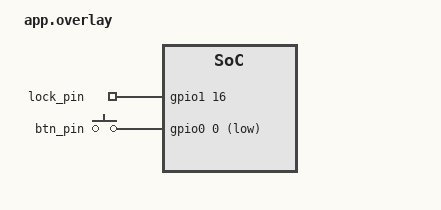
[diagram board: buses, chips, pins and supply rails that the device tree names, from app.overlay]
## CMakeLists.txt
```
# SPDX-License-Identifier: Apache-2.0

cmake_minimum_required(VERSION 3.20.0)

list(APPEND EXTRA_DTC_OVERLAY_FILE ${CMAKE_CURRENT_SOURCE_DIR}/app.overlay)

find_package(Zephyr REQUIRED HINTS $ENV{ZEPHYR_BASE})
project(elock)

target_sources(app PRIVATE
    src/main.c
    src/lock_ctrl.c
    src/button.c
    src/wifi_manager.c
    src/http_server.c
)

target_include_directories(app PRIVATE src)

zephyr_linker_sources(SECTIONS sections-rom.ld)

generate_inc_file_for_target(app
    src/web/index.html
    ${ZEPHYR_BINARY_DIR}/include/generated/index_html.inc)
```

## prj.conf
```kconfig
# --- WiFi (ESP32 driver) ---
CONFIG_WIFI=y
CONFIG_WIFI_NM=y
CONFIG_WIFI_ESP32=y
CONFIG_WIFI_USAGE_MODE_STA_AP=y

# --- Networking ---
CONFIG_NETWORKING=y
CONFIG_NET_CONFIG_AUTO_INIT=n
CONFIG_NET_CONNECTION_MANAGER=y
CONFIG_NET_IPV4=y
CONFIG_NET_TCP=y
CONFIG_NET_UDP=y
CONFIG_NET_SOCKETS=y
CONFIG_NET_DHCPV4=y
CONFIG_NET_DHCPV4_SERVER=y
CONFIG_NET_L2_ETHERNET=y
CONFIG_NET_L2_WIFI_MGMT=y
CONFIG_NET_MGMT=y
CONFIG_NET_MGMT_EVENT=y
CONFIG_NET_MGMT_EVENT_INFO=y
CONFIG_NET_MGMT_EVENT_QUEUE_SIZE=10
CONFIG_NET_MGMT_EVENT_STACK_SIZE=4096
CONFIG_NET_IF_MAX_IPV4_COUNT=2
CONFIG_NET_IF_MAX_IPV6_COUNT=2
CONFIG_NET_PKT_RX_COUNT=16
CONFIG_NET_PKT_TX_COUNT=16

# --- POSIX needed by HTTP server (eventfd, etc.) ---
CONFIG_POSIX_API=y
CONFIG_EVENTFD=y
CONFIG_ZVFS_EVENTFD_MAX=8
CONFIG_ZVFS_POLL_MAX=16

# --- HTTP server (HTTP/1.1 only, no TLS) ---
CONFIG_HTTP_PARSER=y
CONFIG_HTTP_PARSER_URL=y
CONFIG_HTTP_SERVER=y
CONFIG_HTTP_SERVER_MAX_CLIENTS=3
CONFIG_HTTP_SERVER_MAX_URL_LENGTH=128

# --- Settings on NVS for WiFi credential persistence ---
CONFIG_FLASH=y
CONFIG_FLASH_MAP=y
CONFIG_NVS=y
CONFIG_SETTINGS=y
CONFIG_SETTINGS_NVS=y

# --- GPIO + logging ---
CONFIG_GPIO=y
CONFIG_LOG=y
CONFIG_NET_LOG=y

# --- Stacks ---
CONFIG_MAIN_STACK_SIZE=4096
CONFIG_SYSTEM_WORKQUEUE_STACK_SIZE=2048

# --- Reboot ---
CONFIG_REBOOT=y
```

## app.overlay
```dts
/ {
    wifi_ap: wifi_ap {
        compatible = "espressif,esp32-wifi";
        status = "okay";
    };

    aliases {
        lock-out = &lock_gpio_node;
        btn-lock = &btn_gpio_node;
    };

    lock_gpio_node: lock-output {
        compatible = "gpio-leds";
        lock_pin: lock_pin {
            gpios = <&gpio1 16 GPIO_ACTIVE_HIGH>;
        };
    };

    btn_gpio_node: lock-button {
        compatible = "gpio-keys";
        btn_pin: btn_pin {
            gpios = <&gpio0 0 (GPIO_ACTIVE_LOW | GPIO_PULL_UP)>;
        };
    };
};
```

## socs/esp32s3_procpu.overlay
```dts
/ {
    chosen {
        zephyr,console = &usb_serial;
        zephyr,shell-uart = &usb_serial;
    };
};
&usb_serial {
    status = "okay";
};
```

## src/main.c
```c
#include <zephyr/kernel.h>
#include <zephyr/logging/log.h>

#include "button.h"
#include "http_server.h"
#include "lock_ctrl.h"
#include "wifi_manager.h"

LOG_MODULE_REGISTER(main, LOG_LEVEL_INF);

int main(void)
{
	LOG_INF("SmartLock boot");

	if (lock_ctrl_init() < 0) {
		LOG_ERR("lock_ctrl_init failed");
	}
	if (button_init() < 0) {
		LOG_ERR("button_init failed");
	}
	if (wifi_manager_init() < 0) {
		LOG_ERR("wifi_manager_init failed");
	}
	if (http_server_thread_init() < 0) {
		LOG_ERR("http_server_thread_init failed");
	}

	return 0;
}
```

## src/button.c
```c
#include <zephyr/kernel.h>
#include <zephyr/drivers/gpio.h>
#include <zephyr/logging/log.h>

#include "button.h"
#include "lock_ctrl.h"

LOG_MODULE_REGISTER(button, LOG_LEVEL_INF);

#define BTN_NODE DT_CHILD(DT_ALIAS(btn_lock), btn_pin)
BUILD_ASSERT(DT_NODE_EXISTS(BTN_NODE), "btn-lock alias / btn_pin child missing");

static const struct gpio_dt_spec btn_gpio = GPIO_DT_SPEC_GET(BTN_NODE, gpios);

#define BUTTON_THREAD_STACK_SIZE 1024
#define BUTTON_THREAD_PRIORITY   3
#define BUTTON_POLL_MS           10
#define BUTTON_DEBOUNCE_MS       50

static K_THREAD_STACK_DEFINE(button_thread_stack, BUTTON_THREAD_STACK_SIZE);
static struct k_thread button_thread_data;

static void button_thread_entry(void *p1, void *p2, void *p3)
{
	ARG_UNUSED(p1);
	ARG_UNUSED(p2);
	ARG_UNUSED(p3);

	bool last_stable = false;
	bool candidate = false;
	int64_t candidate_since = 0;

	while (1) {
		int raw = gpio_pin_get_dt(&btn_gpio);

		if (raw < 0) {
			k_msleep(BUTTON_POLL_MS);
			continue;
		}

		bool pressed = raw != 0;

		if (pressed != candidate) {
			candidate = pressed;
			candidate_since = k_uptime_get();
		} else if (candidate != last_stable &&
			   (k_uptime_get() - candidate_since) >= BUTTON_DEBOUNCE_MS) {
			last_stable = candidate;
			if (last_stable) {
				LOG_INF("Button pressed -> lock");
				lock_ctrl_lock();
			}
		}

		k_msleep(BUTTON_POLL_MS);
	}
}

int button_init(void)
{
	int ret;

	if (!gpio_is_ready_dt(&btn_gpio)) {
		LOG_ERR("Button GPIO not ready");
		return -ENODEV;
	}

	ret = gpio_pin_configure_dt(&btn_gpio, GPIO_INPUT);
	if (ret < 0) {
		LOG_ERR("Configure button GPIO failed: %d", ret);
		return ret;
	}

	k_thread_create(&button_thread_data, button_thread_stack,
			K_THREAD_STACK_SIZEOF(button_thread_stack),
			button_thread_entry, NULL, NULL, NULL,
			BUTTON_THREAD_PRIORITY, 0, K_NO_WAIT);
	k_thread_name_set(&button_thread_data, "button_thread");

	return 0;
}
```

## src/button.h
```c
#ifndef ELOCK_BUTTON_H_
#define ELOCK_BUTTON_H_

/*
 * Owns GPIO0 with internal pull-up. A dedicated polling thread
 * (button_thread) debounces 50ms in software and calls lock_ctrl_lock()
 * on press.
 */

int button_init(void);

#endif /* ELOCK_BUTTON_H_ */
```

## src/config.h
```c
#ifndef ELOCK_CONFIG_H_
#define ELOCK_CONFIG_H_

#define LOCK_PIN_CODE           "123456"
#define LOCK_UNLOCK_DURATION_S  5

#define WIFI_RETRY_COUNT        5
#define WIFI_RETRY_DELAY_MS     3000
#define WIFI_AP_SSID            "SmartLock-Setup"
#define WIFI_AP_CHANNEL         6
#define WIFI_AP_IP              "192.168.4.1"
#define WIFI_AP_NETMASK         "255.255.255.0"

#define HTTP_SERVER_PORT        80

#define SETTINGS_KEY_WIFI_SSID  "elock/wifi/ssid"
#define SETTINGS_KEY_WIFI_PSK   "elock/wifi/psk"

#define WIFI_SSID_MAX_LEN       32
#define WIFI_PSK_MAX_LEN        64

#endif /* ELOCK_CONFIG_H_ */
```

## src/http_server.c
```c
#include <string.h>
#include <stdio.h>

#include <zephyr/kernel.h>
#include <zephyr/logging/log.h>
#include <zephyr/net/http/server.h>
#include <zephyr/net/http/service.h>
#include <zephyr/net/http/status.h>

#include "config.h"
#include "http_server.h"
#include "lock_ctrl.h"
#include "wifi_manager.h"

LOG_MODULE_REGISTER(http_srv, LOG_LEVEL_INF);

#define HTTP_THREAD_STACK_SIZE 4096
#define HTTP_THREAD_PRIORITY   7

static K_THREAD_STACK_DEFINE(http_thread_stack, HTTP_THREAD_STACK_SIZE);
static struct k_thread http_thread_data;

#define POST_BUF_SIZE 256

static const uint8_t index_html[] = {
#include "index_html.inc"
};

static const char config_html[] =
	"<!doctype html><html><head><meta charset=\"utf-8\">"
	"<title>SmartLock Setup</title></head><body>"
	"<h1>WiFi Setup</h1>"
	"<form method=\"POST\" action=\"/config\">"
	"<p><label>SSID: <input name=\"ssid\" maxlength=\"32\" required></label></p>"
	"<p><label>Password: <input name=\"password\" type=\"password\" maxlength=\"64\"></label></p>"
	"<button type=\"submit\">Save & Reboot</button>"
	"</form></body></html>";

static const char unlock_ok_body[]   = "OK";
static const char unlock_bad_body[]  = "Invalid PIN";
static const char config_ok_body[]   = "Saved. Rebooting...";
static const char not_found_body[]   = "Not found";
static const char bad_request_body[] = "Bad request";

static int find_form_field(const char *body, size_t body_len,
			   const char *key, char *out, size_t out_size)
{
	size_t key_len = strlen(key);
	const char *p = body;
	const char *end = body + body_len;

	while (p < end) {
		const char *amp = memchr(p, '&', end - p);
		const char *seg_end = amp ? amp : end;

		if ((size_t)(seg_end - p) > key_len &&
		    p[key_len] == '=' &&
		    memcmp(p, key, key_len) == 0) {
			const char *vstart = p + key_len + 1;
			size_t vlen = seg_end - vstart;

			if (vlen >= out_size) {
				return -ENOMEM;
			}
			memcpy(out, vstart, vlen);
			out[vlen] = '\0';
			return (int)vlen;
		}

		if (!amp) {
			break;
		}
		p = amp + 1;
	}

	return -ENOENT;
}

static int collect_body(enum http_transaction_status status,
			const struct http_request_ctx *req,
			uint8_t *buf, size_t buf_size, size_t *cursor)
{
	if (status == HTTP_SERVER_TRANSACTION_ABORTED ||
	    status == HTTP_SERVER_TRANSACTION_COMPLETE) {
		*cursor = 0;
		return -EAGAIN;
	}

	if (req->data_len + *cursor > buf_size) {
		*cursor = 0;
		return -ENOMEM;
	}

	memcpy(buf + *cursor, req->data, req->data_len);
	*cursor += req->data_len;

	if (status == HTTP_SERVER_REQUEST_DATA_FINAL) {
		return 0;
	}
	return -EINPROGRESS;
}

static void set_text_response(struct http_response_ctx *resp,
			      enum http_status status,
			      const char *body, size_t body_len)
{
	static const struct http_header text_headers[] = {
		{.name = "Content-Type", .value = "text/plain"},
	};

	resp->status = status;
	resp->headers = text_headers;
	resp->header_count = ARRAY_SIZE(text_headers);
	resp->body = (const uint8_t *)body;
	resp->body_len = body_len;
	resp->final_chunk = true;
}

static int index_handler(struct http_client_ctx *client,
			 enum http_transaction_status status,
			 const struct http_request_ctx *request_ctx,
			 struct http_response_ctx *response_ctx,
			 void *user_data)
{
	ARG_UNUSED(client);
	ARG_UNUSED(request_ctx);
	ARG_UNUSED(user_data);

	if (status != HTTP_SERVER_REQUEST_DATA_FINAL) {
		return 0;
	}

	static const struct http_header html_headers[] = {
		{.name = "Content-Type", .value = "text/html"},
	};

	response_ctx->status = HTTP_200_OK;
	response_ctx->headers = html_headers;
	response_ctx->header_count = ARRAY_SIZE(html_headers);
	response_ctx->body = index_html;
	response_ctx->body_len = sizeof(index_html);
	response_ctx->final_chunk = true;
	return 0;
}

static int status_handler(struct http_client_ctx *client,
			  enum http_transaction_status status,
			  const struct http_request_ctx *request_ctx,
			  struct http_response_ctx *response_ctx,
			  void *user_data)
{
	ARG_UNUSED(client);
	ARG_UNUSED(request_ctx);
	ARG_UNUSED(user_data);

	if (status != HTTP_SERVER_REQUEST_DATA_FINAL) {
		return 0;
	}

	static char body[160];
	const char *ip = wifi_manager_get_ip();
	int n;

	if (ip[0]) {
		n = snprintf(body, sizeof(body),
			     "{\"locked\":%s,\"wifi\":\"%s\",\"ip\":\"%s\","
			     "\"temp\":null,\"humidity\":null}",
			     lock_ctrl_is_locked() ? "true" : "false",
			     wifi_manager_get_state(), ip);
	} else {
		n = snprintf(body, sizeof(body),
			     "{\"locked\":%s,\"wifi\":\"%s\",\"ip\":null,"
			     "\"temp\":null,\"humidity\":null}",
			     lock_ctrl_is_locked() ? "true" : "false",
			     wifi_manager_get_state());
	}

	if (n < 0 || n >= (int)sizeof(body)) {
		response_ctx->status = HTTP_500_INTERNAL_SERVER_ERROR;
		response_ctx->final_chunk = true;
		return 0;
	}

	static const struct http_header json_headers[] = {
		{.name = "Content-Type", .value = "application/json"},
		{.name = "Cache-Control", .value = "no-store"},
	};

	response_ctx->status = HTTP_200_OK;
	response_ctx->headers = json_headers;
	response_ctx->header_count = ARRAY_SIZE(json_headers);
	response_ctx->body = (const uint8_t *)body;
	response_ctx->body_len = n;
	response_ctx->final_chunk = true;
	return 0;
}

static struct http_resource_detail_dynamic status_detail = {
	.common = {
		.type = HTTP_RESOURCE_TYPE_DYNAMIC,
		.bitmask_of_supported_http_methods = BIT(HTTP_GET),
	},
	.cb = status_handler,
};

static struct http_resource_detail_dynamic index_detail = {
	.common = {
		.type = HTTP_RESOURCE_TYPE_DYNAMIC,
		.bitmask_of_supported_http_methods = BIT(HTTP_GET),
	},
	.cb = index_handler,
};

static int unlock_handler(struct http_client_ctx *client,
			  enum http_transaction_status status,
			  const struct http_request_ctx *request_ctx,
			  struct http_response_ctx *response_ctx,
			  void *user_data)
{
	ARG_UNUSED(client);
	ARG_UNUSED(user_data);

	static uint8_t buf[POST_BUF_SIZE];
	static size_t cursor;

	int rc = collect_body(status, request_ctx, buf, sizeof(buf), &cursor);

	if (rc == -EINPROGRESS) {
		return 0;
	}
	if (rc == -EAGAIN) {
		return 0;
	}
	if (rc == -ENOMEM) {
		set_text_response(response_ctx, HTTP_400_BAD_REQUEST,
				  bad_request_body, sizeof(bad_request_body) - 1);
		return 0;
	}

	char pin[16];
	int got = find_form_field((const char *)buf, cursor, "pin",
				  pin, sizeof(pin));
	cursor = 0;

	if (got < 0) {
		set_text_response(response_ctx, HTTP_400_BAD_REQUEST,
				  bad_request_body, sizeof(bad_request_body) - 1);
		return 0;
	}

	if (strcmp(pin, LOCK_PIN_CODE) == 0) {
		LOG_INF("PIN OK -> unlock");
		lock_ctrl_unlock();
		set_text_response(response_ctx, HTTP_200_OK,
				  unlock_ok_body, sizeof(unlock_ok_body) - 1);
	} else {
		LOG_WRN("PIN rejected");
		set_text_response(response_ctx, HTTP_403_FORBIDDEN,
				  unlock_bad_body, sizeof(unlock_bad_body) - 1);
	}
	return 0;
}

static struct http_resource_detail_dynamic unlock_detail = {
	.common = {
		.type = HTTP_RESOURCE_TYPE_DYNAMIC,
		.bitmask_of_supported_http_methods = BIT(HTTP_POST),
	},
	.cb = unlock_handler,
};

static int config_handler(struct http_client_ctx *client,
			  enum http_transaction_status status,
			  const struct http_request_ctx *request_ctx,
			  struct http_response_ctx *response_ctx,
			  void *user_data)
{
	ARG_UNUSED(client);
	ARG_UNUSED(user_data);

	static uint8_t buf[POST_BUF_SIZE];
	static size_t cursor;

	if (wifi_manager_mode() != WIFI_MGR_MODE_AP) {
		if (status != HTTP_SERVER_REQUEST_DATA_FINAL) {
			return 0;
		}
		set_text_response(response_ctx, HTTP_404_NOT_FOUND,
				  not_found_body, sizeof(not_found_body) - 1);
		return 0;
	}

	if (client->method == HTTP_GET) {
		if (status != HTTP_SERVER_REQUEST_DATA_FINAL) {
			return 0;
		}
		static const struct http_header html_headers[] = {
			{.name = "Content-Type", .value = "text/html"},
		};
		response_ctx->status = HTTP_200_OK;
		response_ctx->headers = html_headers;
		response_ctx->header_count = ARRAY_SIZE(html_headers);
		response_ctx->body = (const uint8_t *)config_html;
		response_ctx->body_len = sizeof(config_html) - 1;
		response_ctx->final_chunk = true;
		return 0;
	}

	int rc = collect_body(status, request_ctx, buf, sizeof(buf), &cursor);

	if (rc == -EINPROGRESS || rc == -EAGAIN) {
		return 0;
	}
	if (rc == -ENOMEM) {
		set_text_response(response_ctx, HTTP_400_BAD_REQUEST,
				  bad_request_body, sizeof(bad_request_body) - 1);
		return 0;
	}

	char ssid[WIFI_SSID_MAX_LEN + 1];
	char psk[WIFI_PSK_MAX_LEN + 1];

	int s = find_form_field((const char *)buf, cursor, "ssid",
				ssid, sizeof(ssid));
	int p = find_form_field((const char *)buf, cursor, "password",
				psk, sizeof(psk));
	cursor = 0;

	if (s <= 0) {
		set_text_response(response_ctx, HTTP_400_BAD_REQUEST,
				  bad_request_body, sizeof(bad_request_body) - 1);
		return 0;
	}
	if (p < 0) {
		psk[0] = '\0';
	}

	if (wifi_manager_save_credentials(ssid, psk) < 0) {
		set_text_response(response_ctx, HTTP_400_BAD_REQUEST,
				  bad_request_body, sizeof(bad_request_body) - 1);
		return 0;
	}

	LOG_INF("Credentials saved, scheduling reboot");
	wifi_manager_schedule_reboot(1000);

	set_text_response(response_ctx, HTTP_200_OK,
			  config_ok_body, sizeof(config_ok_body) - 1);
	return 0;
}

static struct http_resource_detail_dynamic config_detail = {
	.common = {
		.type = HTTP_RESOURCE_TYPE_DYNAMIC,
		.bitmask_of_supported_http_methods = BIT(HTTP_GET) | BIT(HTTP_POST),
	},
	.cb = config_handler,
};

static uint16_t http_service_port = HTTP_SERVER_PORT;
HTTP_SERVICE_DEFINE(elock_http_service, NULL, &http_service_port,
		    CONFIG_HTTP_SERVER_MAX_CLIENTS, 4, NULL, NULL, NULL);

HTTP_RESOURCE_DEFINE(elock_index, elock_http_service, "/", &index_detail);
HTTP_RESOURCE_DEFINE(elock_status, elock_http_service, "/status", &status_detail);
HTTP_RESOURCE_DEFINE(elock_unlock, elock_http_service, "/unlock", &unlock_detail);
HTTP_RESOURCE_DEFINE(elock_config, elock_http_service, "/config", &config_detail);

static void http_thread_entry(void *p1, void *p2, void *p3)
{
	ARG_UNUSED(p1);
	ARG_UNUSED(p2);
	ARG_UNUSED(p3);

	while (!wifi_manager_network_ready()) {
		k_msleep(200);
	}

	int ret = http_server_start();

	if (ret < 0) {
		LOG_ERR("http_server_start failed: %d", ret);
		return;
	}
	LOG_INF("HTTP server started on :%u", HTTP_SERVER_PORT);
}

int http_server_thread_init(void)
{
	k_thread_create(&http_thread_data, http_thread_stack,
			K_THREAD_STACK_SIZEOF(http_thread_stack),
			http_thread_entry, NULL, NULL, NULL,
			HTTP_THREAD_PRIORITY, 0, K_NO_WAIT);
	k_thread_name_set(&http_thread_data, "http_thread");
	return 0;
}
```

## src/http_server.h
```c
#ifndef ELOCK_HTTP_SERVER_H_
#define ELOCK_HTTP_SERVER_H_

/*
 * Spawns http_thread which waits for the network to become ready and then
 * starts the Zephyr HTTP server. Routes are registered statically via
 * HTTP_RESOURCE_DEFINE in http_server.c.
 */

int http_server_thread_init(void);

#endif /* ELOCK_HTTP_SERVER_H_ */
```

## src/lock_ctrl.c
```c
#include <zephyr/kernel.h>
#include <zephyr/drivers/gpio.h>
#include <zephyr/logging/log.h>

#include "config.h"
#include "lock_ctrl.h"

LOG_MODULE_REGISTER(lock_ctrl, LOG_LEVEL_INF);

#define LOCK_NODE DT_CHILD(DT_ALIAS(lock_out), lock_pin)
BUILD_ASSERT(DT_NODE_EXISTS(LOCK_NODE), "lock-out alias / lock_pin child missing");

static const struct gpio_dt_spec lock_gpio = GPIO_DT_SPEC_GET(LOCK_NODE, gpios);

static K_SEM_DEFINE(unlock_request_sem, 0, 1);
static K_SEM_DEFINE(lock_now_sem, 0, 1);

static atomic_t is_unlocked = ATOMIC_INIT(0);

#define LOCK_THREAD_STACK_SIZE 1024
#define LOCK_THREAD_PRIORITY   4

static K_THREAD_STACK_DEFINE(lock_thread_stack, LOCK_THREAD_STACK_SIZE);
static struct k_thread lock_thread_data;

static void lock_thread_entry(void *p1, void *p2, void *p3)
{
	ARG_UNUSED(p1);
	ARG_UNUSED(p2);
	ARG_UNUSED(p3);

	while (1) {
		k_sem_take(&unlock_request_sem, K_FOREVER);

		k_sem_reset(&lock_now_sem);
		gpio_pin_set_dt(&lock_gpio, 1);
		atomic_set(&is_unlocked, 1);
		LOG_INF("Lock: UNLOCKED");

		(void)k_sem_take(&lock_now_sem, K_SECONDS(LOCK_UNLOCK_DURATION_S));

		gpio_pin_set_dt(&lock_gpio, 0);
		atomic_set(&is_unlocked, 0);
		LOG_INF("Lock: LOCKED");
	}
}

int lock_ctrl_init(void)
{
	int ret;

	if (!gpio_is_ready_dt(&lock_gpio)) {
		LOG_ERR("Lock GPIO not ready");
		return -ENODEV;
	}

	ret = gpio_pin_configure_dt(&lock_gpio, GPIO_OUTPUT_INACTIVE);
	if (ret < 0) {
		LOG_ERR("Configure lock GPIO failed: %d", ret);
		return ret;
	}

	k_thread_create(&lock_thread_data, lock_thread_stack,
			K_THREAD_STACK_SIZEOF(lock_thread_stack),
			lock_thread_entry, NULL, NULL, NULL,
			LOCK_THREAD_PRIORITY, 0, K_NO_WAIT);
	k_thread_name_set(&lock_thread_data, "lock_thread");

	return 0;
}

void lock_ctrl_unlock(void)
{
	k_sem_give(&unlock_request_sem);
}

void lock_ctrl_lock(void)
{
	gpio_pin_set_dt(&lock_gpio, 0);
	atomic_set(&is_unlocked, 0);
	k_sem_give(&lock_now_sem);
}

bool lock_ctrl_is_locked(void)
{
	return atomic_get(&is_unlocked) == 0;
}
```

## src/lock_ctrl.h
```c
#ifndef ELOCK_LOCK_CTRL_H_
#define ELOCK_LOCK_CTRL_H_

/*
 * Owns GPIO48 lock output and an internal "lock_thread" that handles the
 * timed unlock sequence (HIGH for LOCK_UNLOCK_DURATION_S, then LOW). All
 * public calls are non-blocking.
 */

#include <stdbool.h>

int  lock_ctrl_init(void);
void lock_ctrl_unlock(void);
void lock_ctrl_lock(void);
bool lock_ctrl_is_locked(void);

#endif /* ELOCK_LOCK_CTRL_H_ */
```

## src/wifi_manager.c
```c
#include <string.h>

#include <zephyr/kernel.h>
#include <zephyr/logging/log.h>
#include <zephyr/net/net_if.h>
#include <zephyr/net/net_ip.h>
#include <zephyr/net/wifi_mgmt.h>
#include <zephyr/net/dhcpv4_server.h>
#include <zephyr/settings/settings.h>
#include <zephyr/sys/reboot.h>

#include "config.h"
#include "wifi_manager.h"

LOG_MODULE_REGISTER(wifi_manager, LOG_LEVEL_INF);

#define WIFI_THREAD_STACK_SIZE 4096
#define WIFI_THREAD_PRIORITY   5

#define WIFI_EVENT_MASK                                                                            \
	(NET_EVENT_WIFI_CONNECT_RESULT | NET_EVENT_WIFI_DISCONNECT_RESULT |                        \
	 NET_EVENT_WIFI_AP_ENABLE_RESULT | NET_EVENT_WIFI_AP_DISABLE_RESULT)

#define IPV4_EVENT_MASK (NET_EVENT_IPV4_ADDR_ADD | NET_EVENT_IPV4_ADDR_DEL)

static K_THREAD_STACK_DEFINE(wifi_thread_stack, WIFI_THREAD_STACK_SIZE);
static struct k_thread wifi_thread_data;

static struct net_mgmt_event_callback wifi_cb;
static struct net_mgmt_event_callback ipv4_cb;

static char ip_str[NET_IPV4_ADDR_LEN];

static char saved_ssid[WIFI_SSID_MAX_LEN + 1];
static char saved_psk[WIFI_PSK_MAX_LEN + 1];
static size_t saved_ssid_len;
static size_t saved_psk_len;

static enum wifi_mgr_mode current_mode = WIFI_MGR_MODE_BOOT;
static bool network_ready;

static K_SEM_DEFINE(wifi_connect_sem, 0, 1);
static int last_connect_status = -1;

static void reboot_work_handler(struct k_work *work);
static K_WORK_DELAYABLE_DEFINE(reboot_work, reboot_work_handler);

static int wifi_settings_set(const char *name, size_t len,
			     settings_read_cb read_cb, void *cb_arg)
{
	const char *next;
	ssize_t rc;

	if (settings_name_steq(name, "ssid", &next) && !next) {
		if (len > WIFI_SSID_MAX_LEN) {
			return -EINVAL;
		}
		rc = read_cb(cb_arg, saved_ssid, len);
		if (rc < 0) {
			return rc;
		}
		saved_ssid[rc] = '\0';
		saved_ssid_len = rc;
		return 0;
	}

	if (settings_name_steq(name, "psk", &next) && !next) {
		if (len > WIFI_PSK_MAX_LEN) {
			return -EINVAL;
		}
		rc = read_cb(cb_arg, saved_psk, len);
		if (rc < 0) {
			return rc;
		}
		saved_psk[rc] = '\0';
		saved_psk_len = rc;
		return 0;
	}

	return -ENOENT;
}

SETTINGS_STATIC_HANDLER_DEFINE(elock_wifi, "elock/wifi", NULL,
			       wifi_settings_set, NULL, NULL);

static void wifi_event_handler(struct net_mgmt_event_callback *cb,
			       uint64_t mgmt_event, struct net_if *iface)
{
	ARG_UNUSED(iface);

	switch (mgmt_event) {
	case NET_EVENT_WIFI_CONNECT_RESULT: {
		const struct wifi_status *status = (const struct wifi_status *)cb->info;

		last_connect_status = status->status;
		k_sem_give(&wifi_connect_sem);
		if (status->status == 0) {
			LOG_INF("STA connected");
			network_ready = true;
		} else {
			LOG_WRN("STA connect failed: %d", status->status);
		}
		break;
	}
	case NET_EVENT_WIFI_DISCONNECT_RESULT:
		LOG_INF("STA disconnected");
		break;
	case NET_EVENT_WIFI_AP_ENABLE_RESULT:
		LOG_INF("AP enabled");
		network_ready = true;
		break;
	case NET_EVENT_WIFI_AP_DISABLE_RESULT:
		LOG_INF("AP disabled");
		break;
	default:
		break;
	}
}

static void ipv4_event_handler(struct net_mgmt_event_callback *cb,
			       uint64_t mgmt_event, struct net_if *iface)
{
	ARG_UNUSED(iface);

	if (mgmt_event == NET_EVENT_IPV4_ADDR_ADD) {
		const struct in_addr *addr = (const struct in_addr *)cb->info;

		if (addr) {
			net_addr_ntop(AF_INET, addr, ip_str, sizeof(ip_str));
			LOG_INF("IPv4 addr: %s", ip_str);
		}
	} else if (mgmt_event == NET_EVENT_IPV4_ADDR_DEL) {
		ip_str[0] = '\0';
	}
}

static int load_credentials(void)
{
	int rc = settings_load_subtree("elock/wifi");

	if (rc < 0) {
		LOG_WRN("settings_load_subtree(elock/wifi) failed: %d", rc);
		return rc;
	}
	return saved_ssid_len > 0 ? 0 : -ENOENT;
}

static int try_sta_connect(void)
{
	struct net_if *iface = net_if_get_wifi_sta();
	struct wifi_connect_req_params params = {0};

	if (!iface) {
		LOG_ERR("STA iface not available");
		return -ENODEV;
	}

	params.ssid = (const uint8_t *)saved_ssid;
	params.ssid_length = saved_ssid_len;
	if (saved_psk_len > 0) {
		params.psk = (const uint8_t *)saved_psk;
		params.psk_length = saved_psk_len;
		params.security = WIFI_SECURITY_TYPE_PSK;
	} else {
		params.security = WIFI_SECURITY_TYPE_NONE;
	}
	params.channel = WIFI_CHANNEL_ANY;
	params.band = WIFI_FREQ_BAND_2_4_GHZ;
	params.mfp = WIFI_MFP_OPTIONAL;

	current_mode = WIFI_MGR_MODE_CONNECTING;

	for (int attempt = 1; attempt <= WIFI_RETRY_COUNT; attempt++) {
		LOG_INF("STA connect attempt %d/%d to '%s'", attempt,
			WIFI_RETRY_COUNT, saved_ssid);

		k_sem_reset(&wifi_connect_sem);
		last_connect_status = -1;

		int ret = net_mgmt(NET_REQUEST_WIFI_CONNECT, iface, &params,
				   sizeof(params));
		if (ret) {
			LOG_WRN("NET_REQUEST_WIFI_CONNECT failed: %d", ret);
		} else if (k_sem_take(&wifi_connect_sem,
				      K_MSEC(WIFI_RETRY_DELAY_MS * 4)) == 0 &&
			   last_connect_status == 0) {
			current_mode = WIFI_MGR_MODE_STA;
			return 0;
		}

		k_msleep(WIFI_RETRY_DELAY_MS);
	}

	return -ETIMEDOUT;
}

static int enable_ap_mode(void)
{
	struct net_if *iface = net_if_get_wifi_sap();
	struct wifi_connect_req_params params = {0};
	struct in_addr ap_addr;
	struct in_addr ap_netmask;
	struct in_addr dhcp_base;
	int ret;

	if (!iface) {
		LOG_ERR("AP iface not available");
		return -ENODEV;
	}

	if (net_addr_pton(AF_INET, WIFI_AP_IP, &ap_addr) < 0 ||
	    net_addr_pton(AF_INET, WIFI_AP_NETMASK, &ap_netmask) < 0) {
		LOG_ERR("Invalid AP IP/netmask");
		return -EINVAL;
	}

	net_if_ipv4_set_gw(iface, &ap_addr);
	if (!net_if_ipv4_addr_add(iface, &ap_addr, NET_ADDR_MANUAL, 0)) {
		LOG_WRN("Could not add AP IP");
	}
	if (!net_if_ipv4_set_netmask_by_addr(iface, &ap_addr, &ap_netmask)) {
		LOG_WRN("Could not set AP netmask");
	}

	dhcp_base = ap_addr;
	dhcp_base.s4_addr[3] += 10;
	if (net_dhcpv4_server_start(iface, &dhcp_base) != 0) {
		LOG_WRN("DHCPv4 server start failed");
	}

	params.ssid = (const uint8_t *)WIFI_AP_SSID;
	params.ssid_length = sizeof(WIFI_AP_SSID) - 1;
	params.psk_length = 0;
	params.security = WIFI_SECURITY_TYPE_NONE;
	params.channel = WIFI_AP_CHANNEL;
	params.band = WIFI_FREQ_BAND_2_4_GHZ;
	params.mfp = WIFI_MFP_DISABLE;

	ret = net_mgmt(NET_REQUEST_WIFI_AP_ENABLE, iface, &params, sizeof(params));
	if (ret) {
		LOG_ERR("NET_REQUEST_WIFI_AP_ENABLE failed: %d", ret);
		return ret;
	}

	current_mode = WIFI_MGR_MODE_AP;
	strncpy(ip_str, WIFI_AP_IP, sizeof(ip_str) - 1);
	ip_str[sizeof(ip_str) - 1] = '\0';
	network_ready = true;
	return 0;
}

static void wifi_thread_entry(void *p1, void *p2, void *p3)
{
	ARG_UNUSED(p1);
	ARG_UNUSED(p2);
	ARG_UNUSED(p3);

	int rc;

	rc = settings_subsys_init();
	if (rc < 0) {
		LOG_ERR("settings_subsys_init failed: %d", rc);
	} else {
		(void)load_credentials();
	}

	net_mgmt_init_event_callback(&wifi_cb, wifi_event_handler, WIFI_EVENT_MASK);
	net_mgmt_add_event_callback(&wifi_cb);

	net_mgmt_init_event_callback(&ipv4_cb, ipv4_event_handler, IPV4_EVENT_MASK);
	net_mgmt_add_event_callback(&ipv4_cb);

	if (saved_ssid_len > 0) {
		LOG_INF("Found saved SSID, attempting STA");
		if (try_sta_connect() == 0) {
			return;
		}
		LOG_WRN("STA failed, falling back to AP");
	} else {
		LOG_INF("No saved credentials, starting AP");
	}

	if (enable_ap_mode() != 0) {
		LOG_ERR("AP mode failed to start");
	}
}

int wifi_manager_init(void)
{
	k_thread_create(&wifi_thread_data, wifi_thread_stack,
			K_THREAD_STACK_SIZEOF(wifi_thread_stack),
			wifi_thread_entry, NULL, NULL, NULL,
			WIFI_THREAD_PRIORITY, 0, K_NO_WAIT);
	k_thread_name_set(&wifi_thread_data, "wifi_thread");
	return 0;
}

enum wifi_mgr_mode wifi_manager_mode(void)
{
	return current_mode;
}

bool wifi_manager_network_ready(void)
{
	return network_ready;
}

const char *wifi_manager_get_state(void)
{
	switch (current_mode) {
	case WIFI_MGR_MODE_STA:
		return "sta";
	case WIFI_MGR_MODE_AP:
		return "ap";
	case WIFI_MGR_MODE_CONNECTING:
		return "connecting";
	case WIFI_MGR_MODE_BOOT:
	default:
		return "boot";
	}
}

const char *wifi_manager_get_ip(void)
{
	return ip_str;
}

int wifi_manager_save_credentials(const char *ssid, const char *psk)
{
	int rc;

	if (!ssid) {
		return -EINVAL;
	}

	size_t ssid_len = strnlen(ssid, WIFI_SSID_MAX_LEN + 1);
	size_t psk_len = psk ? strnlen(psk, WIFI_PSK_MAX_LEN + 1) : 0;

	if (ssid_len == 0 || ssid_len > WIFI_SSID_MAX_LEN ||
	    psk_len > WIFI_PSK_MAX_LEN) {
		return -EINVAL;
	}

	rc = settings_save_one(SETTINGS_KEY_WIFI_SSID, ssid, ssid_len);
	if (rc < 0) {
		LOG_ERR("save ssid failed: %d", rc);
		return rc;
	}

	rc = settings_save_one(SETTINGS_KEY_WIFI_PSK, psk ? psk : "", psk_len);
	if (rc < 0) {
		LOG_ERR("save psk failed: %d", rc);
		return rc;
	}

	return 0;
}

static void reboot_work_handler(struct k_work *work)
{
	ARG_UNUSED(work);
	LOG_INF("Rebooting now");
	sys_reboot(SYS_REBOOT_COLD);
}

void wifi_manager_schedule_reboot(int delay_ms)
{
	k_work_schedule(&reboot_work, K_MSEC(delay_ms));
}
```

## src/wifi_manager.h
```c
#ifndef ELOCK_WIFI_MANAGER_H_
#define ELOCK_WIFI_MANAGER_H_

#include <stdbool.h>
#include <stddef.h>

/*
 * WiFi state machine: BOOT -> (load NVS) -> STA_CONNECT or AP_MODE,
 * with AP_MODE fallback after WIFI_RETRY_COUNT failures. Runs on its
 * own wifi_thread.
 */

enum wifi_mgr_mode {
	WIFI_MGR_MODE_BOOT,
	WIFI_MGR_MODE_CONNECTING,
	WIFI_MGR_MODE_AP,
	WIFI_MGR_MODE_STA,
};

int  wifi_manager_init(void);
enum wifi_mgr_mode wifi_manager_mode(void);
bool wifi_manager_network_ready(void);

/* Lowercase status string per TASK-002: "sta" / "ap" / "connecting" / "boot". */
const char *wifi_manager_get_state(void);

/*
 * Current IPv4 address as a NUL-terminated string ("192.168.4.1" in AP mode,
 * DHCP-assigned in STA, "" if not yet known).
 */
const char *wifi_manager_get_ip(void);

/*
 * Persist WiFi credentials to Settings. Returns 0 on success.
 * Both ssid and psk are NUL-terminated strings.
 */
int  wifi_manager_save_credentials(const char *ssid, const char *psk);

/*
 * Schedule a cold reboot after delay_ms via the system work queue.
 */
void wifi_manager_schedule_reboot(int delay_ms);

#endif /* ELOCK_WIFI_MANAGER_H_ */
```
